# GD32F50x register map
File version: 1.0
CPU: CM33 r2p1, little endian, MPU, FPU, 4 interrupt priority bits
Registers are 32-bit, read-write, reset 0x0 unless marked. A register's access mark holds for its fields unless they carry their own. Offsets are from the block's base; [hi:lo] are bit positions; {n}, {i} and the like mark numbered series.

## TIMER1 — General-purpose-timers
Base 0x40000000
Same registers: TIMER2 0x40000400, TIMER3 0x40000800, TIMER4 0x40000C00
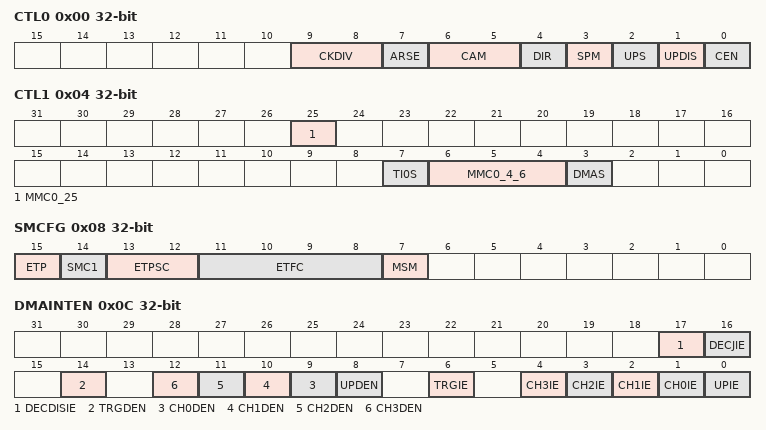
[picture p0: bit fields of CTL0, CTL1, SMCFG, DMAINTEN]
0x00 CTL0 — Control register 0
  [9:8] CKDIV — Clock division
  [7] ARSE — Auto-reload shadow enable
  [6:5] CAM — Counter align mode selection
  [4] DIR — Direction
  [3] SPM — Single pulse mode
  [2] UPS — Update source
  [1] UPDIS — Update disable
  [0] CEN — Counter enable
0x04 CTL1 — Control register 1
  [25] MMC0_25 — Master mode control 0
  [7] TI0S — Channel 0 trigger input selection
  [6:4] MMC0_4_6 — Master mode control 0
  [3] DMAS — DMA request source selection
0x08 SMCFG — Slave mode configuration register
  [15] ETP — External trigger polarity
  [14] SMC1 — Part of slave mode controller is used to enable external clock mode 1
  [13:12] ETPSC — External trigger prescaler
  [11:8] ETFC — External trigger filter control
  [7] MSM — Master-slave mode
0x0C DMAINTEN — DMA and interrupt enable register
  [17] DECDISIE — Quadrature decoder signal disconnection interrupt enable
  [16] DECJIE — Quadrature decoder signal jump (the two signals jump at the same time) interrupt enable
  [14] TRGDEN — Trigger DMA request enable
  [n+9] CH{n}DEN (n=0..3) — Channel {n} capture/compare DMA request enable
  [8] UPDEN — Update DMA request enable
  [6] TRGIE — Trigger interrupt enable
  [n+1] CH{n}IE (n=0..3) — Channel {n} capture/compare interrupt enable
  [0] UPIE — Update interrupt enable
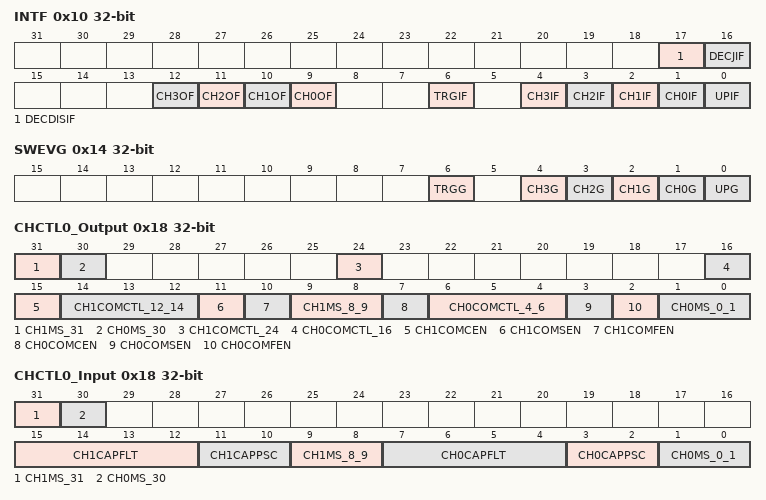
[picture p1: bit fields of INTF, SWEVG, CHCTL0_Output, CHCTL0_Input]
0x10 INTF — Interrupt flag register
  [17] DECDISIF — Quadrature decoder signal disconnection interrupt flag
  [16] DECJIF — Quadrature decoder signal jump (the two signals jump at the same time) interrupt flag
  [n+9] CH{n}OF (n=0..3) — Channel {n} over capture flag
  [6] TRGIF — Trigger interrupt flag
  [n+1] CH{n}IF (n=0..3) — Channel {n} capture/compare interrupt flag
  [0] UPIF — Update interrupt flag
0x14 SWEVG wo — Software event generation register
  [6] TRGG — Trigger event generation
  [n+1] CH{n}G (n=0..3) — Channel {n} capture or compare event generation
  [0] UPG — Update event generation
0x18 CHCTL0_Output — Channel control register 0 (output mode)
  [31] CH1MS_31 — Channel 0 I/O mode selection
  [30] CH0MS_30 — Channel 0 I/O mode selection
  [24] CH1COMCTL_24 — Channel 1 compare output control
  [16] CH0COMCTL_16 — Channel 0 compare output control
  [15] CH1COMCEN — Channel 1 output compare clear enable
  [14:12] CH1COMCTL_12_14 — Channel 1 compare output control
  [11] CH1COMSEN — Channel 1 output compare shadow enable
  [10] CH1COMFEN — Channel 1 output compare fast enable
  [9:8] CH1MS_8_9 — Channel 1 mode selection
  [7] CH0COMCEN — Channel 0 output compare clear enable
  [6:4] CH0COMCTL_4_6 — Channel 0 compare output control
  [3] CH0COMSEN — Channel 0 compare output shadow enable
  [2] CH0COMFEN — Channel 0 output compare fast enable
  [1:0] CH0MS_0_1 — Channel 0 I/O mode selection
0x18 CHCTL0_Input (alternate view of CHCTL0_Output) — Channel control register 0 (input mode)
  [31] CH1MS_31 — Channel 0 I/O mode selection
  [30] CH0MS_30 — Channel 0 I/O mode selection
  [15:12] CH1CAPFLT — Channel 1 input capture filter control
  [11:10] CH1CAPPSC — Channel 1 input capture prescaler
  [9:8] CH1MS_8_9 — Channel 1 mode selection
  [7:4] CH0CAPFLT — Channel 0 input capture filter control
  [3:2] CH0CAPPSC — Channel 0 input capture prescaler
  [1:0] CH0MS_0_1 — Channel 0 mode selection
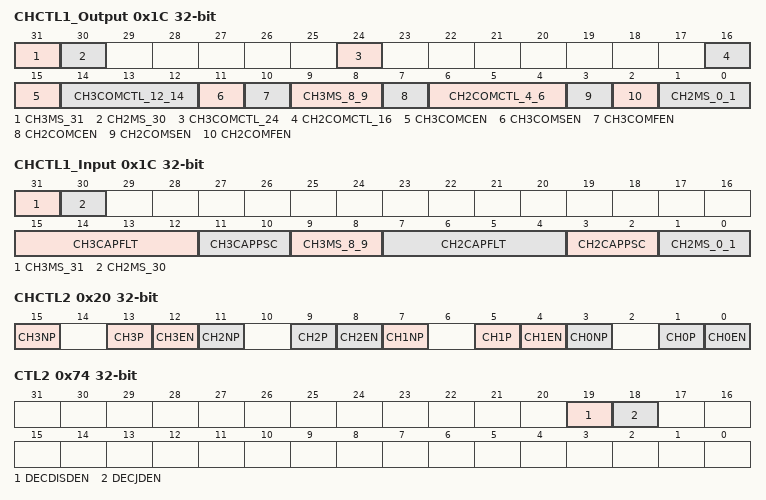
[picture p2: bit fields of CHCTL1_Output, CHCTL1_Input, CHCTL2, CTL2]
0x1C CHCTL1_Output — Channel control register 1 (output mode)
  [31] CH3MS_31 — Channel 3 I/O mode selection
  [30] CH2MS_30 — Channel 2 I/O mode selection
  [24] CH3COMCTL_24 — Channel 3 compare output control
  [16] CH2COMCTL_16 — Channel 2 compare output control
  [15] CH3COMCEN — Channel 3 output compare clear enable
  [14:12] CH3COMCTL_12_14 — Channel 3 compare output control
  [11] CH3COMSEN — Channel 3 output compare shadow enable
  [10] CH3COMFEN — Channel 3 output compare fast enable
  [9:8] CH3MS_8_9 — Channel 3 mode selection
  [7] CH2COMCEN — Channel 2 output compare clear enable
  [6:4] CH2COMCTL_4_6 — Channel 2 compare output control
  [3] CH2COMSEN — Channel 2 compare output shadow enable
  [2] CH2COMFEN — Channel 2 output compare fast enable
  [1:0] CH2MS_0_1 — Channel 2 I/O mode selection
0x1C CHCTL1_Input (alternate view of CHCTL1_Output) — Channel control register 1 (input mode)
  [31] CH3MS_31 — Channel 3 I/O mode selection
  [30] CH2MS_30 — Channel 2 I/O mode selection
  [15:12] CH3CAPFLT — Channel 3 input capture filter control
  [11:10] CH3CAPPSC — Channel 3 input capture prescaler
  [9:8] CH3MS_8_9 — Channel 3 mode selection
  [7:4] CH2CAPFLT — Channel 2 input capture filter control
  [3:2] CH2CAPPSC — Channel 2 input capture prescaler
  [1:0] CH2MS_0_1 — Channel 2 mode selection
0x20 CHCTL2 — Channel control register 2
  [15] CH3NP — Channel 3 complementary capture/compare polarity
  [4n+1] CH{n}P (n=0..3) — Channel {n} capture/compare function polarity
  [4n] CH{n}EN (n=0..3) — Channel {n} capture/compare function enable
  [11] CH2NP — Channel 2 complementary capture/compare polarity
  [7] CH1NP — Channel 1 complementary capture/compare polarity
  [3] CH0NP — Channel 0 complementary output polarity
0x24 CNT — Counter register
  [31:0] CNT — This bit-field indicates the current counter value
0x28 PSC — Prescaler register
  [15:0] PSC — Prescaler value of the counter clock
0x2C CAR reset 0xFFFFFFFF — Counter auto reload register
  [31:0] CARL — Counter auto reload value
{0x34+4i} CH{i}CV (i=0..3) — Channel {i} capture/compare value register
  [31:0] CH{i}VAL — Capture/compare value of channel {i}
0x74 CTL2 — Control register 2
  [19] DECDISDEN — Quadrature decoder signal disconnection detection enable
  [18] DECJDEN — Quadrature decoder signal jump (the two signals jump at the same time) detection enable
0x94 WDGPER reset 0xFFFFFFFF — Watchdog counter period registe
  [31:0] WDGPER — Watchdog counter period value
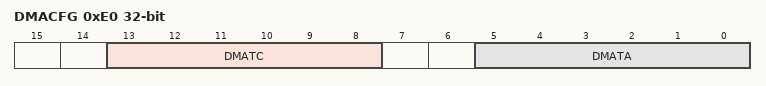
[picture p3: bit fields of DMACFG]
0xE0 DMACFG — DMA configuration register
  [13:8] DMATC — DMA transfer count
  [5:0] DMATA — DMA transfer access start address
0xE4 DMATB — DMA transfer buffer register
  [31:0] DMATB — DMA transfer buffer
0xFC CFG — Configuration register
  [1] CHVSEL — Write CHxVAL register selection bit
